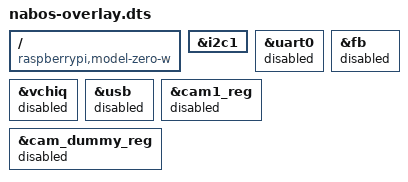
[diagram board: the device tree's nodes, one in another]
/dts-v1/;
/plugin/;

/ {
    compatible = "raspberrypi,model-zero-w", "raspberrypi,model-zero-2-w";
};

/*
 * Linux-only hardware profile. NixOS merges it at build time into
 * the slot's vendor DTB, which U-Boot loads for Linux; the firmware partition
 * keeps the pristine DTB for U-Boot itself. Labels are those of the locked
 * bcm2708-rpi-zero-w and bcm2710-rpi-zero-2-w DTBs.
 *
 * Left enabled on purpose: mini UART (console), SD card and SDIO Wi-Fi,
 * firmware mailbox, watchdog, RNG, thermal, OTP, ACT LED.
 * Analog audio, SPI and video are disabled in the vendor DTB. The LED
 * overlay claims PWM1 separately when this profile is merged.
 */

/* Audio codec and userspace RFID/NFC readers share GPIO 2/3 on I2C bus 1. */
&i2c1 { status = "okay"; };

/* PL011 only carries the Bluetooth chip, which NabOS does not use. */
&uart0 { status = "disabled"; };
/* Headless; config.txt also sets max_framebuffers=0. */
&fb { status = "disabled"; };
/* VideoCore multimedia services (HDMI audio, camera, codecs). */
&vchiq { status = "disabled"; };
/* No USB device is used. */
&usb { status = "disabled"; };
/* No camera. */
&cam1_reg { status = "disabled"; };
&cam_dummy_reg { status = "disabled"; };
